# STM32C031 register map
File version: 1.4
CPU: CM0 r0p0, little endian, MPU, FPU, 4 interrupt priority bits
Registers are 32-bit, read-write, reset 0x0 unless marked. A register's access mark holds for its fields unless they carry their own. Offsets are from the block's base; [hi:lo] are bit positions; 'fields as' and 'values as' point back to an identical list; <NAME> marks a mode.

## TIM14 — General-purpose timers
Base 0x40002000
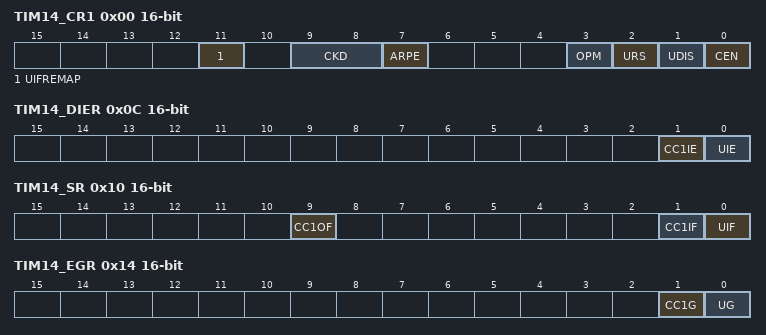
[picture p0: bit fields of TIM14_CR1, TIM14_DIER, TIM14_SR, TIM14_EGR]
0x00 TIM14_CR1 16-bit — TIM14 control register 1
  [11] UIFREMAP — UIF status bit remapping
    0=No remapping. UIF status bit is not copied to TIMx_CNT register bit 31.; 1=Remapping enabled. UIF status bit is copied to TIMx_CNT register bit 31.
  [9:8] CKD — Clock division This bit-field indicates the division ratio between the timer clock (CK_INT) frequency and sampling clock used by the digital filters (TIx),
    0=tDTS = tCK_INT; 1=tDTS = 2 tCK_INT; 2=tDTS = 4 tCK_INT
  [7] ARPE — Auto-reload preload enable
    0=TIMx_ARR register is not buffered; 1=TIMx_ARR register is buffered
  [3] OPM — One-pulse mode
    0=Counter is not stopped on the update event; 1=Counter stops counting on the next update event (clearing the CEN bit)
  [2] URS — Update request source This bit is set and cleared by software to select the update interrupt (UEV) sources. Counter overflow Setting the UG bit
    0=Any of the following events generate an UEV if enabled:; 1=Only counter overflow generates an UEV if enabled
  [1] UDIS — Update disable This bit is set and cleared by software to enable/disable update interrupt (UEV) event generation. Counter overflow Setting the UG bit. Buffered registers are then loaded with their preload values.
    0=UEV enabled. An UEV is generated by one of the following events:; 1=UEV disabled. No UEV is generated, shadow registers keep their value (ARR, PSC, CCRx). The counter and the prescaler are reinitialized if the UG bit is set.
  [0] CEN — Counter enable Note: External clock and gated mode can work only if the CEN bit has been previously set by software. However trigger mode can set the CEN bit automatically by hardware.
    0=Counter disabled; 1=Counter enabled
0x0C TIM14_DIER 16-bit — TIM14 Interrupt enable register
  [1] CC1IE — Capture/Compare 1 interrupt enable
    0=CC1 interrupt disabled; 1=CC1 interrupt enabled
  [0] UIE — Update interrupt enable
    0=Update interrupt disabled; 1=Update interrupt enabled
0x10 TIM14_SR 16-bit — TIM14 status register
  [9] CC1OF — Capture/Compare 1 overcapture flag This flag is set by hardware only when the corresponding channel is configured in input capture mode. It is cleared by software by writing it to 0.
    0=No overcapture has been detected; 1=The counter value has been captured in TIMx_CCR1 register while CC1IF flag was already set
  [1] CC1IF — Capture/compare 1 interrupt flag This flag is set by hardware. It is cleared by software (input capture or output compare mode) or by reading the TIMx_CCR1 register (input capture mode only). If channel CC1 is configured as output: this flag is set when he content of the counter TIMx_CNT matches the content of the TIMx_CCR1 register. When the content of TIMx_CCR1 is greater than the content of TIMx_ARR, the CC1IF bit goes high on the counter overflow (in up-counting and up/down-counting modes) or underflow (in down-counting mode). There are 3 possible options for flag setting in center-aligned mode, refer to the CMS bits in the TIMx_CR1 register for the full description. If channel CC1 is configured as input: this bit is set when counter value has been captured in TIMx_CCR1 register (an edge has been detected on IC1, as per the edge sensitivity defined with the CC1P and CC1NP bits setting, in TIMx_CCER).
    0=No compare match / No input capture occurred; 1=A compare match or an input capture occurred
  [0] UIF — Update interrupt flag This bit is set by hardware on an update event. It is cleared by software. At overflow and if UDIS=0 in the TIMx_CR1 register. When CNT is reinitialized by software using the UG bit in TIMx_EGR register, if URS=0 and UDIS=0 in the TIMx_CR1 register.
    0=No update occurred; 1=Update interrupt pending. This bit is set by hardware when the registers are updated:
0x14 TIM14_EGR 16-bit wo — TIM14 event generation register
  [1] CC1G — Capture/compare 1 generation This bit is set by software in order to generate an event, it is automatically cleared by hardware. If channel CC1 is configured as output: CC1IF flag is set, Corresponding interrupt or is sent if enabled. If channel CC1 is configured as input: The current value of the counter is captured in TIMx_CCR1 register. The CC1IF flag is set, the corresponding interrupt is sent if enabled. The CC1OF flag is set if the CC1IF flag was already high.
    0=No action; 1=A capture/compare event is generated on channel 1:
  [0] UG — Update generation This bit can be set by software, it is automatically cleared by hardware.
    0=No action; 1=Re-initialize the counter and generates an update of the registers. Note that the prescaler counter is cleared too (anyway the prescaler ratio is not affected). The counter is cleared.
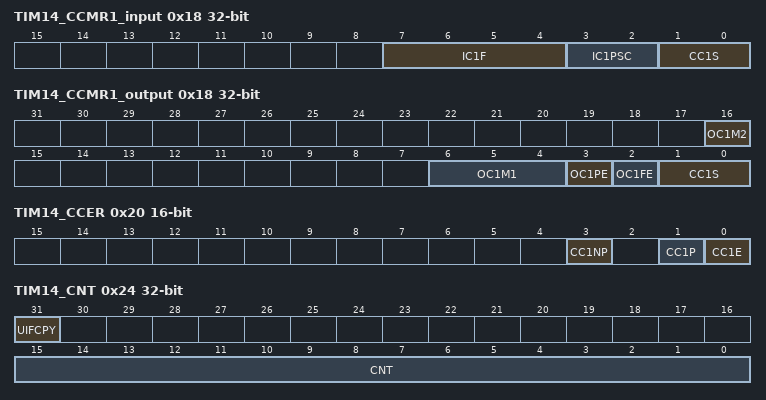
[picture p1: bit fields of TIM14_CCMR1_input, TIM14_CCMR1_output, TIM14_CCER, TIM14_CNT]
0x18 TIM14_CCMR1_input — TIM14 capture/compare mode register 1 [alternate]
  [7:4] IC1F — Input capture 1 filter This bit-field defines the frequency used to sample TI1 input and the length of the digital filter applied to TI1. The digital filter is made of an event counter in which N consecutive events are needed to validate a transition on the output:
    0=No filter, sampling is done at fDTS; 1=fSAMPLING=fCK_INT, N=2; 2=fSAMPLING=fCK_INT, N=4; 3=fSAMPLING=fCK_INT, N=8; 4=fSAMPLING=fDTS/2, N=6; 5=fSAMPLING=fDTS/2, N=8; 6=fSAMPLING=fDTS/4, N=6; 7=fSAMPLING=fDTS/4, N=8; 8=fSAMPLING=fDTS/8, N=6; 9=fSAMPLING=fDTS/8, N=8; 10=fSAMPLING=fDTS/16, N=5; 11=fSAMPLING=fDTS/16, N=6; 12=fSAMPLING=fDTS/16, N=8; 13=fSAMPLING=fDTS/32, N=5; 14=fSAMPLING=fDTS/32, N=6; 15=fSAMPLING=fDTS/32, N=8
  [3:2] IC1PSC — Input capture 1 prescaler This bit-field defines the ratio of the prescaler acting on CC1 input (IC1). The prescaler is reset as soon as CC1E=0 (TIMx_CCER register).
    0=no prescaler, capture is done each time an edge is detected on the capture input; 1=capture is done once every 2 events; 2=capture is done once every 4 events; 3=capture is done once every 8 events
  [1:0] CC1S — Capture/Compare 1 selection This bit-field defines the direction of the channel (input/output) as well as the used input. Note: CC1S bits are writable only when the channel is OFF (CC1E = 0 in TIMx_CCER).
    0=CC1 channel is configured as output; 1=CC1 channel is configured as input, IC1 is mapped on TI1
0x18 TIM14_CCMR1_output (alternate view of TIM14_CCMR1_input) — TIM14 capture/compare mode register 1 [alternate]
  [16] OC1M2 — Output compare 1 mode (refer to bit 16 for OC1M[3]) These bits define the behavior of the output reference signal OC1REF from which OC1 is derived. OC1REF is active high whereas OC1 active level depends on CC1P bit. Others: Reserved Note: In PWM mode 1 or 2, the OCREF level changes when the result of the comparison changes or when the output compare mode switches from frozen to PWM mode. Note: The OC1M[3] bit is not contiguous, located in bit 16.
    0=Frozen. The comparison between the output compare register TIMx_CCR1 and the counter TIMx_CNT has no effect on the outputs.; 1=Set channel 1 to active level on match. OC1REF signal is forced high when the counter TIMx_CNT matches the capture/compare register 1 (TIMx_CCR1).
  [6:4] OC1M1 — Output compare 1 mode (refer to bit 16 for OC1M[3]) These bits define the behavior of the output reference signal OC1REF from which OC1 is derived. OC1REF is active high whereas OC1 active level depends on CC1P bit. Others: Reserved Note: In PWM mode 1 or 2, the OCREF level changes when the result of the comparison changes or when the output compare mode switches from frozen to PWM mode. Note: The OC1M[3] bit is not contiguous, located in bit 16.
    0=Frozen. The comparison between the output compare register TIMx_CCR1 and the counter TIMx_CNT has no effect on the outputs.; 1=Set channel 1 to active level on match. OC1REF signal is forced high when the counter TIMx_CNT matches the capture/compare register 1 (TIMx_CCR1).; 2=Set channel 1 to inactive level on match. OC1REF signal is forced low when the counter TIMx_CNT matches the capture/compare register 1 (TIMx_CCR1).; 3=Toggle - OC1REF toggles when TIMx_CNT = TIMx_CCR1; 4=Force inactive level - OC1REF is forced low; 5=Force active level - OC1REF is forced high; 6=PWM mode 1 - Channel 1 is active as long as TIMx_CNT < TIMx_CCR1 else inactive; 7=PWM mode 2 - Channel 1 is inactive as long as TIMx_CNT < TIMx_CCR1 else active
  [3] OC1PE — Output compare 1 preload enable Note: The PWM mode can be used without validating the preload register only in one pulse mode (OPM bit set in TIMx_CR1 register). Else the behavior is not guaranteed.
    0=Preload register on TIMx_CCR1 disabled. TIMx_CCR1 can be written at anytime, the new value is taken in account immediately.; 1=Preload register on TIMx_CCR1 enabled. Read/Write operations access the preload register. TIMx_CCR1 preload value is loaded in the active register at each update event.
  [2] OC1FE — Output compare 1 fast enable This bit decreases the latency between a trigger event and a transition on the timer output. It must be used in one-pulse mode (OPM bit set in TIMx_CR1 register), to have the output pulse starting as soon as possible after the starting trigger.
    0=CC1 behaves normally depending on counter and CCR1 values even when the trigger is ON. The minimum delay to activate CC1 output when an edge occurs on the trigger input is 5 clock cycles.; 1=An active edge on the trigger input acts like a compare match on CC1 output. OC is then set to the compare level independently of the result of the comparison. Delay to sample the trigger input and to activate CC1 output is reduced to 3 clock cycles. OC1FE acts only if the channel is configured in PWM1 or PWM2 mode.
  [1:0] CC1S — Capture/Compare 1 selection This bit-field defines the direction of the channel (input/output) as well as the used input. Note: CC1S bits are writable only when the channel is OFF (CC1E = 0 in TIMx_CCER).
    values as TIM14_CCMR1_input.CC1S
0x20 TIM14_CCER 16-bit — TIM14 capture/compare enable register
  [3] CC1NP — Capture/Compare 1 complementary output Polarity. CC1 channel configured as output: CC1NP must be kept cleared. CC1 channel configured as input: CC1NP bit is used in conjunction with CC1P to define TI1FP1 polarity (refer to CC1P description).
  [1] CC1P — Capture/Compare 1 output Polarity. When CC1 channel is configured as input, both CC1NP/CC1P bits select the active polarity of TI1FP1 and TI2FP1 for trigger or capture operations. CC1NP=0, CC1P=0: non-inverted/rising edge. The circuit is sensitive to TIxFP1 rising edge (capture or trigger operations in reset, external clock or trigger mode), TIxFP1 is not inverted (trigger operation in gated mode or encoder mode). CC1NP=0, CC1P=1: inverted/falling edge. The circuit is sensitive to TIxFP1 falling edge (capture or trigger operations in reset, external clock or trigger mode), TIxFP1 is inverted (trigger operation in gated mode or encoder mode). CC1NP=1, CC1P=1: non-inverted/both edges/ The circuit is sensitive to both TIxFP1 rising and falling edges (capture or trigger operations in reset, external clock or trigger mode), TIxFP1is not inverted (trigger operation in gated mode). This configuration must not be used in encoder mode. CC1NP=1, CC1P=0: This configuration is reserved, it must not be used.
    0=OC1 active high (output mode) / Edge sensitivity selection (input mode, see below); 1=OC1 active low (output mode) / Edge sensitivity selection (input mode, see below)
  [0] CC1E — Capture/Compare 1 output enable.
    0=Capture mode disabled / OC1 is not active; 1=Capture mode enabled / OC1 signal is output on the corresponding output pin
0x24 TIM14_CNT — TIM14 counter
  [31] UIFCPY — UIF Copy This bit is a read-only copy of the UIF bit in the TIMx_ISR register.
  [15:0] CNT — Counter value
0x28 TIM14_PSC 16-bit — TIM14 prescaler
  [15:0] PSC — Prescaler value The counter clock frequency CK_CNT is equal to fCK_PSC / (PSC[15:0] + 1). PSC contains the value to be loaded in the active prescaler register at each update event. (including when the counter is cleared through UG bit of TIMx_EGR register or through trigger controller when configured in reset mode).
0x2C TIM14_ARR 16-bit reset 0xFFFF — TIM14 auto-reload register
  [15:0] ARR — Auto-reload value ARR is the value to be loaded in the actual auto-reload register. Refer to for more details about ARR update and behavior. The counter is blocked while the auto-reload value is null.
0x34 TIM14_CCR1 16-bit — TIM14 capture/compare register 1
  [15:0] CCR1 — Capture/Compare 1 value If channel CC1 is configured as output: CCR1 is the value to be loaded in the actual capture/compare 1 register (preload value). It is loaded permanently if the preload feature is not selected in the TIMx_CCMR1 register (bit OC1PE). Else the preload value is copied in the active capture/compare 1 register when an update event occurs. The active capture/compare register contains the value to be compared to the counter TIMx_CNT and signaled on OC1 output. If channel CC1is configured as input: CCR1 is the counter value transferred by the last input capture 1 event (IC1).
0x68 TIM14_TISEL 16-bit — TIM14 timer input selection register
  [3:0] TI1SEL — selects TI1[0] to TI1[15] input Others: Reserved
    0=TIM14_CH1 input; 1=RTC CLK; 2=HSE/32; 3=MCO; 4=MCO2
